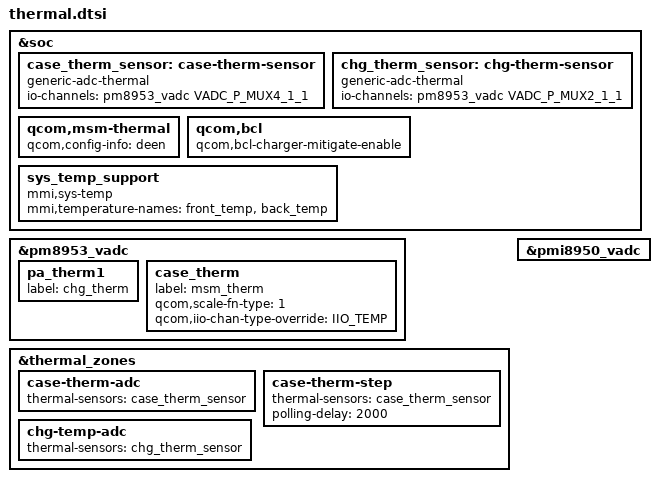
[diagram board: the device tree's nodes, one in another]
/* Copyright (c) 2018, Motorola Mobility Inc. All rights reserved.
 *
 * This program is free software; you can redistribute it and/or modify
 * it under the terms of the GNU General Public License version 2 and
 * only version 2 as published by the Free Software Foundation.
 *
 * This program is distributed in the hope that it will be useful,
 * but WITHOUT ANY WARRANTY; without even the implied warranty of
 * MERCHANTABILITY or FITNESS FOR A PARTICULAR PURPOSE.  See the
 * GNU General Public License for more details.
 */

&soc {
	case_therm_sensor: case-therm-sensor {
		compatible = "generic-adc-thermal";
		#thermal-sensor-cells = <0>;
		io-channels = <&pm8953_vadc VADC_P_MUX4_1_1>;
		io-channel-names = "sensor-channel";
	};

	chg_therm_sensor: chg-therm-sensor {
		compatible = "generic-adc-thermal";
		#thermal-sensor-cells = <0>;
		io-channels = <&pm8953_vadc VADC_P_MUX2_1_1>;
		io-channel-names = "sensor-channel";
	};

	qcom,msm-thermal {
		qcom,config-info = "deen";
	};

	qcom,bcl {
		qcom,bcl-charger-mitigate-enable;
	};

	sys_temp_support {
		compatible = "mmi,sys-temp";
		mmi,temperature-names = "front_temp",
					"back_temp";
		status = "ok";
	};
};

&pm8953_vadc {
	pa_therm1 {
		label = "chg_therm";
	};

	case_therm {
		label = "msm_therm";
		qcom,scale-fn-type = <1>;
		qcom,iio-chan-type-override = "IIO_TEMP";
	};
};

&thermal_zones {
	case-therm-adc {
		thermal-sensors = <&case_therm_sensor>;
	};

	case-therm-step {
		thermal-sensors = <&case_therm_sensor>;
		polling-delay = <2000>;
	};

	chg-temp-adc {
		thermal-sensors = <&chg_therm_sensor>;
	};
};

&pmi8950_vadc {
	/delete-node/ chan@d;
};
